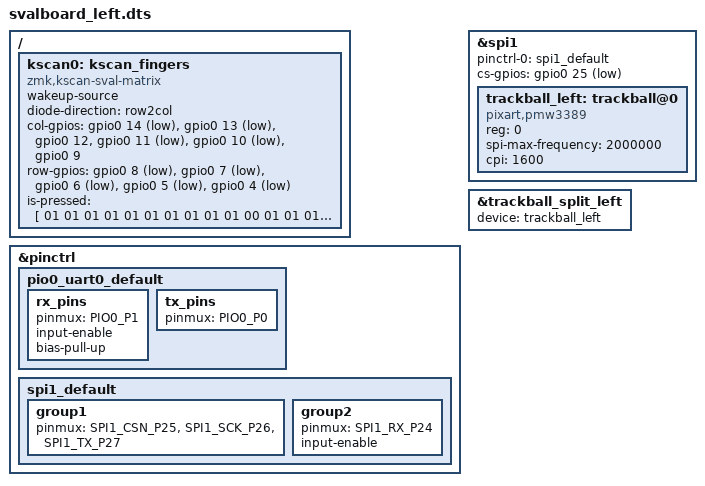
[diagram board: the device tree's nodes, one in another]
/*
 * Copyright (c) 2024 ZMK Contributors
 *
 * SPDX-License-Identifier: MIT
 */

/dts-v1/;
#include "svalboard.dtsi"

/{
    kscan0: kscan_fingers {
	    compatible = "zmk,kscan-sval-matrix";
 		wakeup-source;

        diode-direction = "row2col";
        col-gpios
            = <&gpio0 14 GPIO_ACTIVE_LOW>
            , <&gpio0 13 GPIO_ACTIVE_LOW>
            , <&gpio0 12 GPIO_ACTIVE_HIGH>
            , <&gpio0 11 GPIO_ACTIVE_LOW>
            , <&gpio0 10 GPIO_ACTIVE_LOW>
            , <&gpio0  9 GPIO_ACTIVE_HIGH>
            ;

        row-gpios
            = <&gpio0 8 (GPIO_ACTIVE_LOW)>
	    , <&gpio0 7 (GPIO_ACTIVE_LOW)>
            , <&gpio0 6 (GPIO_ACTIVE_LOW)>
            , <&gpio0 5 (GPIO_ACTIVE_LOW)>
            , <&gpio0 4 (GPIO_ACTIVE_LOW)>
            ;
	is-pressed = [
		01 01 01 01 01 
		01 01 01 01 01
		00 01 01 01 01
		01 01 01 01 01
		01 01 01 01 01
		01 01 01 01 01
	]
	;
    };
};

// rh has row offset 5

&pinctrl {
    pio0_uart0_default: pio0_uart0_default {
        rx_pins {
            pinmux = <PIO0_P1>;
            input-enable;
            bias-pull-up;
        };
        tx_pins {
            pinmux = <PIO0_P0>;
        };
    };
    
    spi1_default: spi1_default {
        group1 {
            pinmux = <SPI1_CSN_P25>, <SPI1_SCK_P26>, <SPI1_TX_P27>;
        };
        group2 {
            pinmux = <SPI1_RX_P24>;
            input-enable;
        };
    };

/*    pio1_ws2812_default: pio1_ws2812_default {
        ws2812 {
            pinmux = <PIO1_P19>;
        };
    };
    */
};

&spi1 {
    status = "okay";
    pinctrl-0 = <&spi1_default>;
    pinctrl-names = "default";
    cs-gpios = <&gpio0 25 GPIO_ACTIVE_LOW>;
    
    trackball_left: trackball@0 {
        compatible = "pixart,pmw3389";
        status = "okay";
        reg = <0>;
        spi-max-frequency = <2000000>;
        cpi = <1600>;
    };
};

&trackball_split_left {
    device = <&trackball_left>;
};
